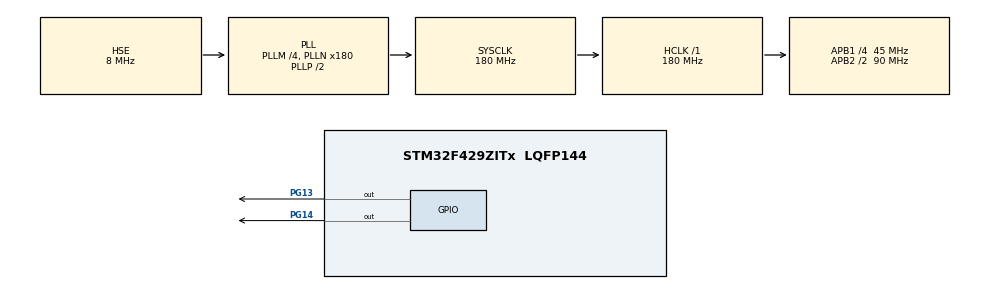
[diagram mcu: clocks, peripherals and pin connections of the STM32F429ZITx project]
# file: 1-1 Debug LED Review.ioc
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Mcu.Family=STM32F4
Mcu.Name=STM32F429ZITx
Mcu.Package=LQFP144
NVIC.PriorityGroup=NVIC_PRIORITYGROUP_4
PG13.Signal=GPIO_Output
PG14.Signal=GPIO_Output
PH0/OSC_IN.Mode=HSE-External-Oscillator
PH0/OSC_IN.Signal=RCC_OSC_IN
PH1/OSC_OUT.Mode=HSE-External-Oscillator
PH1/OSC_OUT.Signal=RCC_OSC_OUT
ProjectManager.HeapSize=0x200
ProjectManager.StackSize=0x400
ProjectManager.TargetToolchain=STM32CubeIDE
RCC.48MHZClocksFreq_Value=90000000
RCC.AHBFreq_Value=180000000
RCC.APB1CLKDivider=RCC_HCLK_DIV4
RCC.APB1Freq_Value=45000000
RCC.APB1TimFreq_Value=90000000
RCC.APB2CLKDivider=RCC_HCLK_DIV2
RCC.APB2Freq_Value=90000000
RCC.APB2TimFreq_Value=180000000
RCC.CortexFreq_Value=180000000
RCC.HCLKFreq_Value=180000000
RCC.HSE_VALUE=8000000
RCC.HSI_VALUE=16000000
RCC.LSE_VALUE=32768
RCC.PLLM=4
RCC.PLLN=180
RCC.PLLSourceVirtual=RCC_PLLSOURCE_HSE
RCC.SYSCLKFreq_VALUE=180000000
RCC.SYSCLKSource=RCC_SYSCLKSOURCE_PLLCLK
RCC.VCOOutputFreq_Value=360000000
board=custom

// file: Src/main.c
/* USER CODE BEGIN Header */
/**
  ******************************************************************************
  * @file           : main.c
  * @brief          : Main program body
  ******************************************************************************
  * @attention
  *
  * <h2><center>&copy; Copyright (c) 2019 STMicroelectronics.
  * All rights reserved.</center></h2>
  *
  * This software component is licensed by ST under BSD 3-Clause license,
  * the "License"; You may not use this file except in compliance with the
  * License. You may obtain a copy of the License at:
  *                        opensource.org/licenses/BSD-3-Clause
  *
  ******************************************************************************
  */
/* USER CODE END Header */

#include "main.h"

void SystemClock_Config(void);
static void MX_GPIO_Init(void);

int main(void)
{

  /* MCU Configuration--------------------------------------------------------*/

  /* Reset of all peripherals, Initializes the Flash interface and the Systick. */
  HAL_Init();

  /* Configure the system clock */
  SystemClock_Config();

  /* Initialize all configured peripherals */
  MX_GPIO_Init();

  /* Infinite loop */
  while (1)
  {

    /* USER CODE BEGIN 3 */
	  LL_GPIO_TogglePin(GPIOG, LL_GPIO_PIN_13 | LL_GPIO_PIN_14);
	  HAL_Delay(500);
  }
  /* USER CODE END 3 */
}

void SystemClock_Config(void)
{
  RCC_OscInitTypeDef RCC_OscInitStruct = {0};
  RCC_ClkInitTypeDef RCC_ClkInitStruct = {0};

  /** Configure the main internal regulator output voltage
  */
  __HAL_RCC_PWR_CLK_ENABLE();
  __HAL_PWR_VOLTAGESCALING_CONFIG(PWR_REGULATOR_VOLTAGE_SCALE1);
  /** Initializes the CPU, AHB and APB busses clocks
  */
  RCC_OscInitStruct.OscillatorType = RCC_OSCILLATORTYPE_HSE;
  RCC_OscInitStruct.HSEState = RCC_HSE_ON;
  RCC_OscInitStruct.PLL.PLLState = RCC_PLL_ON;
  RCC_OscInitStruct.PLL.PLLSource = RCC_PLLSOURCE_HSE;
  RCC_OscInitStruct.PLL.PLLM = 4;
  RCC_OscInitStruct.PLL.PLLN = 180;
  RCC_OscInitStruct.PLL.PLLP = RCC_PLLP_DIV2;
  RCC_OscInitStruct.PLL.PLLQ = 4;
  if (HAL_RCC_OscConfig(&RCC_OscInitStruct) != HAL_OK)
  {
    Error_Handler();
  }
  /** Activate the Over-Drive mode
  */
  if (HAL_PWREx_EnableOverDrive() != HAL_OK)
  {
    Error_Handler();
  }
  /** Initializes the CPU, AHB and APB busses clocks
  */
  RCC_ClkInitStruct.ClockType = RCC_CLOCKTYPE_HCLK|RCC_CLOCKTYPE_SYSCLK
                              |RCC_CLOCKTYPE_PCLK1|RCC_CLOCKTYPE_PCLK2;
  RCC_ClkInitStruct.SYSCLKSource = RCC_SYSCLKSOURCE_PLLCLK;
  RCC_ClkInitStruct.AHBCLKDivider = RCC_SYSCLK_DIV1;
  RCC_ClkInitStruct.APB1CLKDivider = RCC_HCLK_DIV4;
  RCC_ClkInitStruct.APB2CLKDivider = RCC_HCLK_DIV2;

  if (HAL_RCC_ClockConfig(&RCC_ClkInitStruct, FLASH_LATENCY_5) != HAL_OK)
  {
    Error_Handler();
  }
}

static void MX_GPIO_Init(void)
{
  LL_GPIO_InitTypeDef GPIO_InitStruct = {0};

  /* GPIO Ports Clock Enable */
  LL_AHB1_GRP1_EnableClock(LL_AHB1_GRP1_PERIPH_GPIOH);
  LL_AHB1_GRP1_EnableClock(LL_AHB1_GRP1_PERIPH_GPIOG);

  /**/
  LL_GPIO_ResetOutputPin(GPIOG, LL_GPIO_PIN_13|LL_GPIO_PIN_14);

  /**/
  GPIO_InitStruct.Pin = LL_GPIO_PIN_13|LL_GPIO_PIN_14;
  GPIO_InitStruct.Mode = LL_GPIO_MODE_OUTPUT;
  GPIO_InitStruct.Speed = LL_GPIO_SPEED_FREQ_LOW;
  GPIO_InitStruct.OutputType = LL_GPIO_OUTPUT_PUSHPULL;
  GPIO_InitStruct.Pull = LL_GPIO_PULL_NO;
  LL_GPIO_Init(GPIOG, &GPIO_InitStruct);

}

void Error_Handler(void)
{
}

/************************ (C) COPYRIGHT STMicroelectronics *****END OF FILE****/
